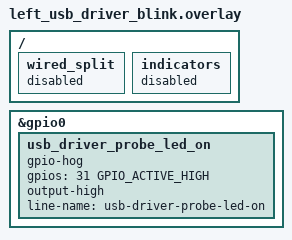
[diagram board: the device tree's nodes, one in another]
/ {
    wired_split {
        status = "disabled";
    };

    indicators {
        status = "disabled";
    };
};

&gpio0 {
    usb_driver_probe_led_on {
        gpio-hog;
        gpios = <31 GPIO_ACTIVE_HIGH>;
        output-high;
        line-name = "usb-driver-probe-led-on";
    };
};
